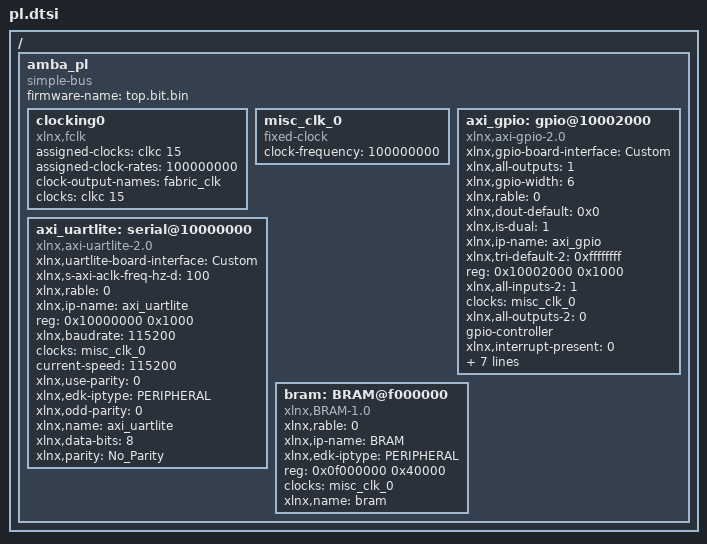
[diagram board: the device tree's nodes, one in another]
/ {
	amba_pl: amba_pl {
		ranges;
		compatible = "simple-bus";
		#address-cells = <1>;
		#size-cells = <1>;
		firmware-name = "top.bit.bin";
		clocking0: clocking0 {
			compatible = "xlnx,fclk";
			assigned-clocks = <&clkc 15>;
			assigned-clock-rates = <100000000>;
			#clock-cells = <0>;
			clock-output-names = "fabric_clk";
			clocks = <&clkc 15>;
		};
		misc_clk_0: misc_clk_0 {
			compatible = "fixed-clock";
			clock-frequency = <100000000>;
			#clock-cells = <0>;
		};
		axi_gpio: gpio@10002000 {
			xlnx,gpio-board-interface = "Custom";
			compatible = "xlnx,axi-gpio-2.0" , "xlnx,xps-gpio-1.00.a";
			xlnx,all-outputs = <1>;
			#gpio-cells = <2>;
			xlnx,gpio-width = <6>;
			xlnx,rable = <0>;
			xlnx,dout-default = <0x0>;
			xlnx,is-dual = <1>;
			xlnx,ip-name = "axi_gpio";
			xlnx,tri-default-2 = <0xffffffff>;
			reg = <0x10002000 0x1000>;
			xlnx,all-inputs-2 = <1>;
			clocks = <&misc_clk_0>;
			xlnx,all-outputs-2 = <0>;
			gpio-controller;
			xlnx,interrupt-present = <0>;
			xlnx,gpio2-board-interface = "sws_2bits";
			xlnx,edk-iptype = "PERIPHERAL";
			xlnx,dout-default-2 = <0x0>;
			status = "okay";
			xlnx,gpio2-width = <2>;
			clock-names = "s_axi_aclk";
			xlnx,tri-default = <0xffffffff>;
			xlnx,name = "axi_gpio";
			xlnx,all-inputs = <0>;
		};
		axi_uartlite: serial@10000000 {
			compatible = "xlnx,axi-uartlite-2.0" , "xlnx,xps-uartlite-1.00.a";
			xlnx,uartlite-board-interface = "Custom";
			xlnx,s-axi-aclk-freq-hz-d = <100>;
			xlnx,rable = <0>;
			xlnx,ip-name = "axi_uartlite";
			reg = <0x10000000 0x1000>;
			xlnx,baudrate = <115200>;
			clocks = <&misc_clk_0>;
			current-speed = <115200>;
			xlnx,use-parity = <0>;
			xlnx,edk-iptype = "PERIPHERAL";
			xlnx,odd-parity = <0>;
			status = "okay";
			clock-names = "s_axi_aclk";
			xlnx,name = "axi_uartlite";
			xlnx,data-bits = <8>;
			xlnx,parity = "No_Parity";
		};
		bram: BRAM@f000000 {
			xlnx,rable = <0>;
			compatible = "xlnx,BRAM-1.0";
			status = "okay";
			clock-names = "s_axi_aclk";
			xlnx,ip-name = "BRAM";
			xlnx,edk-iptype = "PERIPHERAL";
			reg = <0x0f000000 0x40000>;
			clocks = <&misc_clk_0>;
			xlnx,name = "bram";
		};
	};
};
